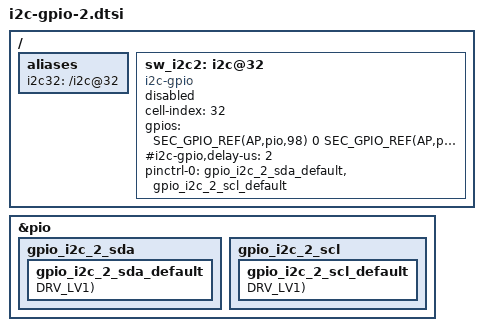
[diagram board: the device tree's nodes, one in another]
&pio {
       gpio_i2c_2_sda {
               gpio_i2c_2_sda_default: gpio_i2c_2_sda_default {
                       GPIO_CONFIG_PUD_DRV(AP,pio,98, FUNC_INPUT, PULL_NONE, DRV_LV1);
               };
       };
};

&pio {
       gpio_i2c_2_scl {
               gpio_i2c_2_scl_default: gpio_i2c_2_scl_default {
                       GPIO_CONFIG_PUD_DRV(AP,pio,6, FUNC_INPUT, PULL_NONE, DRV_LV1);
               };
       };
};

/ {
	fragment@model {
		target-path = "/";
	        __overlay__ {
			aliases {
				  i2c32 = "/i2c@32";
			};
			/* Software I2C */
			sw_i2c2: i2c@32 {
				cell-index = <32>;
				compatible = "i2c-gpio";
				gpios = <
					SEC_GPIO_REF(AP,pio,98) 0 /* SDA */
					SEC_GPIO_REF(AP,pio,6) 0 /* SCL */
					>;
				#i2c-gpio,delay-us = <2>;
				#address-cells = <1>;
				#size-cells = <0>;

				pinctrl-names = "default";
				pinctrl-0 = <
					&gpio_i2c_2_sda_default
					&gpio_i2c_2_scl_default
					>;

				status = "disabled";
			};
		};
	};
};

